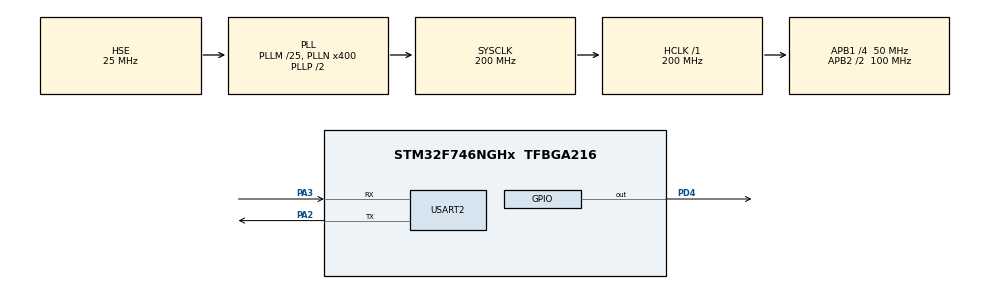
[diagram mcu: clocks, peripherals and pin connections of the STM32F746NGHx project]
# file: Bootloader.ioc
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Mcu.Family=STM32F7
Mcu.Name=STM32F746NGHx
Mcu.Package=TFBGA216
NVIC.PriorityGroup=NVIC_PRIORITYGROUP_4
PA2.Mode=Asynchronous
PA2.Signal=USART2_TX
PA3.Mode=Asynchronous
PA3.Signal=USART2_RX
PD4.Signal=GPIO_Output
PH0/OSC_IN.Mode=HSE-External-Oscillator
PH0/OSC_IN.Signal=RCC_OSC_IN
PH1/OSC_OUT.Mode=HSE-External-Oscillator
PH1/OSC_OUT.Signal=RCC_OSC_OUT
ProjectManager.HeapSize=0x200
ProjectManager.StackSize=0x400
ProjectManager.TargetToolchain=STM32CubeIDE
RCC.AHBFreq_Value=200000000
RCC.APB1CLKDivider=RCC_HCLK_DIV4
RCC.APB1Freq_Value=50000000
RCC.APB1TimFreq_Value=100000000
RCC.APB2CLKDivider=RCC_HCLK_DIV2
RCC.APB2Freq_Value=100000000
RCC.APB2TimFreq_Value=200000000
RCC.CortexFreq_Value=200000000
RCC.HCLKFreq_Value=200000000
RCC.HSE_VALUE=25000000
RCC.HSI_VALUE=16000000
RCC.PLL48CLockSelection=RCC_CLK48SOURCE_PLLSAIP
RCC.PLLI2SN=100
RCC.PLLM=25
RCC.PLLN=400
RCC.PLLQ=9
RCC.PLLSAIN=384
RCC.PLLSAIP=RCC_PLLSAIP_DIV8
RCC.PLLSAIR=5
RCC.PLLSAIRDiv=RCC_PLLSAIDIVR_8
RCC.PLLSourceVirtual=RCC_PLLSOURCE_HSE
RCC.SDMMCClockSelection=RCC_SDMMC1CLKSOURCE_CLK48
RCC.SYSCLKFreq_VALUE=200000000
RCC.SYSCLKSource=RCC_SYSCLKSOURCE_PLLCLK
RCC.USBFreq_Value=48000000
RCC.VCOOutputFreq_Value=400000000
USART2.VirtualMode-Asynchronous=VM_ASYNC
board=STM32F746G-DISCO

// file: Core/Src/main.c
/* USER CODE BEGIN Header */
/**
  ******************************************************************************
  * @file           : main.c
  * @brief          : Main program body
  ******************************************************************************
  * @attention
  *
  * Copyright (c) 2026 STMicroelectronics.
  * All rights reserved.
  *
  * This software is licensed under terms that can be found in the LICENSE file
  * in the root directory of this software component.
  * If no LICENSE file comes with this software, it is provided AS-IS.
  *
  ******************************************************************************
  */
/* USER CODE END Header */
#include "main.h"

/* USER CODE BEGIN Includes */
#include <stdio.h>
/* USER CODE END Includes */

/* USER CODE BEGIN PM */
#define MAJOR 0
#define MINOR 1
/* USER CODE END PM */

UART_HandleTypeDef huart2;

/* USER CODE BEGIN PV */
const uint8_t BL_Version[2] = {MAJOR, MINOR};
/* USER CODE END PV */

void SystemClock_Config(void);
static void MX_GPIO_Init(void);
static void MX_USART2_UART_Init(void);
static void goto_application( void );
/* USER CODE BEGIN PFP */
int _write(int file, char *ptr, int len)
{
    HAL_UART_Transmit(&huart2, (uint8_t *)ptr, len, HAL_MAX_DELAY);
    return len;
}
/* USER CODE END PFP */

int main(void)
{

  /* MCU Configuration--------------------------------------------------------*/

  /* Reset of all peripherals, Initializes the Flash interface and the Systick. */
  HAL_Init();

  /* Configure the system clock */
  SystemClock_Config();

  /* Initialize all configured peripherals */
  MX_GPIO_Init();
  MX_USART2_UART_Init();
  /* USER CODE BEGIN 2 */
  printf("Initialized \r\n");
  /* USER CODE END 2 */

  /* Infinite loop */
  while (1)
  {

    /* USER CODE BEGIN 3 */
	  HAL_GPIO_WritePin(GPIOD, GPIO_PIN_4, GPIO_PIN_RESET);
	  HAL_Delay(3000);
	  HAL_GPIO_WritePin(GPIOD, GPIO_PIN_4, GPIO_PIN_SET);
	  HAL_Delay(1000);
	  goto_application();
  }
  /* USER CODE END 3 */
}

void SystemClock_Config(void)
{
  RCC_OscInitTypeDef RCC_OscInitStruct = {0};
  RCC_ClkInitTypeDef RCC_ClkInitStruct = {0};

  /** Configure the main internal regulator output voltage
  */
  __HAL_RCC_PWR_CLK_ENABLE();
  __HAL_PWR_VOLTAGESCALING_CONFIG(PWR_REGULATOR_VOLTAGE_SCALE1);

  /** Initializes the RCC Oscillators according to the specified parameters
  * in the RCC_OscInitTypeDef structure.
  */
  RCC_OscInitStruct.OscillatorType = RCC_OSCILLATORTYPE_HSE;
  RCC_OscInitStruct.HSEState = RCC_HSE_ON;
  RCC_OscInitStruct.PLL.PLLState = RCC_PLL_ON;
  RCC_OscInitStruct.PLL.PLLSource = RCC_PLLSOURCE_HSE;
  RCC_OscInitStruct.PLL.PLLM = 25;
  RCC_OscInitStruct.PLL.PLLN = 400;
  RCC_OscInitStruct.PLL.PLLP = RCC_PLLP_DIV2;
  RCC_OscInitStruct.PLL.PLLQ = 9;
  if (HAL_RCC_OscConfig(&RCC_OscInitStruct) != HAL_OK)
  {
    Error_Handler();
  }

  /** Activate the Over-Drive mode
  */
  if (HAL_PWREx_EnableOverDrive() != HAL_OK)
  {
    Error_Handler();
  }

  /** Initializes the CPU, AHB and APB buses clocks
  */
  RCC_ClkInitStruct.ClockType = RCC_CLOCKTYPE_HCLK|RCC_CLOCKTYPE_SYSCLK
                              |RCC_CLOCKTYPE_PCLK1|RCC_CLOCKTYPE_PCLK2;
  RCC_ClkInitStruct.SYSCLKSource = RCC_SYSCLKSOURCE_PLLCLK;
  RCC_ClkInitStruct.AHBCLKDivider = RCC_SYSCLK_DIV1;
  RCC_ClkInitStruct.APB1CLKDivider = RCC_HCLK_DIV4;
  RCC_ClkInitStruct.APB2CLKDivider = RCC_HCLK_DIV2;

  if (HAL_RCC_ClockConfig(&RCC_ClkInitStruct, FLASH_LATENCY_6) != HAL_OK)
  {
    Error_Handler();
  }
}

static void MX_USART2_UART_Init(void)
{

  huart2.Instance = USART2;
  huart2.Init.BaudRate = 115200;
  huart2.Init.WordLength = UART_WORDLENGTH_8B;
  huart2.Init.StopBits = UART_STOPBITS_1;
  huart2.Init.Parity = UART_PARITY_NONE;
  huart2.Init.Mode = UART_MODE_TX_RX;
  huart2.Init.HwFlowCtl = UART_HWCONTROL_NONE;
  huart2.Init.OverSampling = UART_OVERSAMPLING_16;
  huart2.Init.OneBitSampling = UART_ONE_BIT_SAMPLE_DISABLE;
  huart2.AdvancedInit.AdvFeatureInit = UART_ADVFEATURE_NO_INIT;
  if (HAL_UART_Init(&huart2) != HAL_OK)
  {
    Error_Handler();
  }

}

static void MX_GPIO_Init(void)
{
  GPIO_InitTypeDef GPIO_InitStruct = {0};

  /* GPIO Ports Clock Enable */
  __HAL_RCC_GPIOD_CLK_ENABLE();
  __HAL_RCC_GPIOH_CLK_ENABLE();
  __HAL_RCC_GPIOA_CLK_ENABLE();

  /*Configure GPIO pin Output Level */
  HAL_GPIO_WritePin(GPIOD, GPIO_PIN_4, GPIO_PIN_RESET);

  /*Configure GPIO pin : PD4 */
  GPIO_InitStruct.Pin = GPIO_PIN_4;
  GPIO_InitStruct.Mode = GPIO_MODE_OUTPUT_PP;
  GPIO_InitStruct.Pull = GPIO_NOPULL;
  GPIO_InitStruct.Speed = GPIO_SPEED_FREQ_LOW;
  HAL_GPIO_Init(GPIOD, &GPIO_InitStruct);

}

/* USER CODE BEGIN 4 */
static void goto_application( void )
{
	printf("Jumping to Application\n");
	void (*app_reset_handler) ( void ) = (void *) (*(volatile uint32_t *)(0x08040000 + 4)); //Application address
/*	To be done if startup file does not have : Reset_Handler:  ldr   sp, =_estack      // set stack pointer //
 * 	__set_MSP((*(volatile uint32_t *) 0x08000000));
 * 	Changed following in linker script:
 * 	FLASH    (rx)    : ORIGIN = 0x8000000,   LENGTH = 64K //Bootloader block size is only 64KB
 * 	*/
	HAL_GPIO_WritePin(GPIOD, GPIO_PIN_4, GPIO_PIN_RESET);
	app_reset_handler(); //call the reset handler
}
/* USER CODE END 4 */

void Error_Handler(void)
{
  __disable_irq();
  while (1)
  {
  }
}
